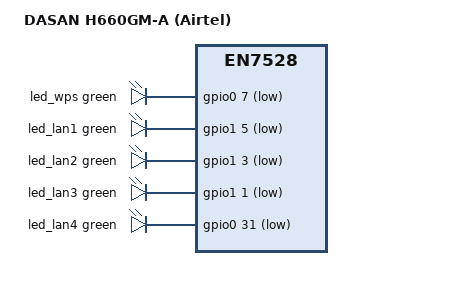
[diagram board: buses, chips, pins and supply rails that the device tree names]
// SPDX-License-Identifier: (GPL-2.0-only OR BSD-2-Clause)
/dts-v1/;

#include "en7528_dasan_h660gm-a.dtsi"

/ {
	model = "DASAN H660GM-A (Airtel)";
	compatible = "dasan,h660gm-a-airtel", "econet,en7528";

	firmware_concat0 {
		compatible = "mtd-concat";
		devices = <&tclinux &unknown_1>;

		partitions {
			compatible = "fixed-partitions";
			#address-cells = <1>;
			#size-cells = <1>;

			econet,boot-flag = <&bootloader_flag 0xfff>;

			partition@0 {
				compatible = "econet,trx";
				label = "firmware";
				reg = <0x0 0x5e80000>;
				econet,enable-remap;
				econet,boot-flag-value = <0>;
			};
		};
	};

	firmware_concat1 {
		compatible = "mtd-concat";
		devices = <&tclinux_slave &unknown_2>;

		partitions {
			compatible = "fixed-partitions";
			#address-cells = <1>;
			#size-cells = <1>;

			econet,boot-flag = <&bootloader_flag 0xfff>;

			partition@0 {
				compatible = "econet,trx";
				label = "firmware2";
				reg = <0x0 0x5e80000>;
				econet,boot-flag-value = <1>;
			};
		};
	};

	leds {
		led_wps: wps {
			color = <LED_COLOR_ID_GREEN>;
			function = LED_FUNCTION_WPS;
			gpios = <&gpio0 7 GPIO_ACTIVE_LOW>;
		};

		led_lan1: lan1 {
			color = <LED_COLOR_ID_GREEN>;
			function = LED_FUNCTION_LAN;
			function-enumerator = <1>;
			gpios = <&gpio1 5 GPIO_ACTIVE_LOW>;
		};

		led_lan2: lan2 {
			color = <LED_COLOR_ID_GREEN>;
			function = LED_FUNCTION_LAN;
			function-enumerator = <2>;
			gpios = <&gpio1 3 GPIO_ACTIVE_LOW>;
		};

		led_lan3: lan3 {
			color = <LED_COLOR_ID_GREEN>;
			function = LED_FUNCTION_LAN;
			function-enumerator = <3>;
			gpios = <&gpio1 1 GPIO_ACTIVE_LOW>;
		};

		led_lan4: lan4 {
			color = <LED_COLOR_ID_GREEN>;
			function = LED_FUNCTION_LAN;
			function-enumerator = <4>;
			gpios = <&gpio0 31 GPIO_ACTIVE_LOW>;
		};
	};
};

&partitions {
	unknown_1: partition@60c0000 {
		label = "unknown_1";
		reg = <0x60c0000 0x3e80000>;
	};

	unknown_2: partition@9f40000 {
		label = "unknown_2";
		reg = <0x9f40000 0x3e80000>;
	};

	partition@ddc0000 {
		label = "reservearea";
		reg = <0xddc0000 0x240000>;
		nvmem-layout {
			compatible = "fixed-layout";
			#address-cells = <1>;
			#size-cells = <1>;

			eeprom_reservearea_40000: eeprom@40000 {
				reg = <0x40000 0x4da8>;
			};

			eeprom_reservearea_1c0000: eeprom@1c0000 {
				reg = <0x1c0000 0x400>;
			};
		};
	};
};
